# STM32U335 register map
File version: 1.0
CPU: CM33 r0p1, little endian, MPU, FPU, 4 interrupt priority bits
Registers are 32-bit, read-write, reset 0x0 unless marked. A register's access mark holds for its fields unless they carry their own. Offsets are from the block's base; [hi:lo] are bit positions; {n}, {i} and the like mark numbered series.

## RCC (part 1 of 2) — RCC register block
Base 0x40030C00
Same registers: RCC_S 0x50030C00
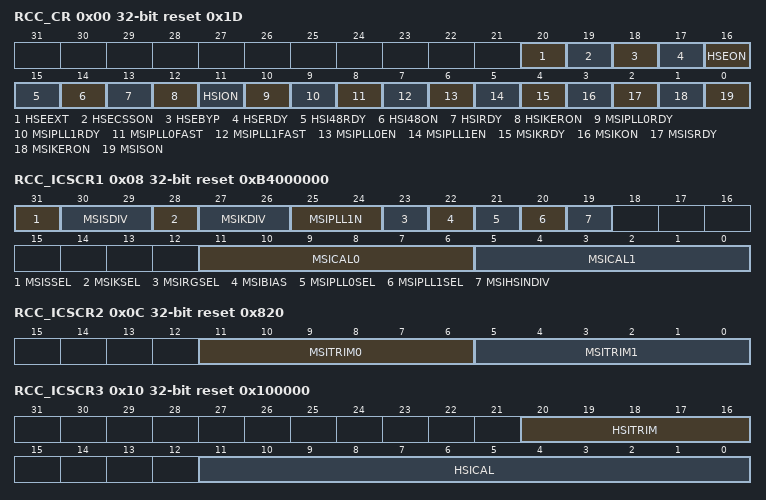
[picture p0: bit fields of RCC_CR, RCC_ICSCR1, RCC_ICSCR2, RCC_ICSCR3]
0x00 RCC_CR reset 0x1D — HSEBYP and HSEEXT are cleared upon power-on reset. They are not affected upon other types of reset.
  [20] HSEEXT — HSE external clock bypass mode Used to select the external clock mode in bypass mode. External clock mode must be configured with HSEON bit to be used by the device. This bit can be written only if the HSE oscillator is disabled. This bit is active only if the HSE bypass mode is enabled.
    0=External HSE clock analog mode; 1=External HSE clock digital mode (through I/O Schmitt trigger)
  [19] HSECSSON — Clock security system enable Used to enable the clock security system. When HSECSSON is set, the clock detector is enabled by hardware when the HSE oscillator is ready, and disabled by hardware if a HSE clock failure is detected. This bit is set only and is cleared by reset.
    0=Clock security system OFF (clock detector OFF); 1=Clock security system ON (clock detector ON if the HSE oscillator is stable, OFF if not)
  [18] HSEBYP — HSE crystal oscillator bypass Used to bypass the oscillator with an external clock. The external clock must be enabled with the HSEON bit set, to be used by the device. The HSEBYP bit can be written only if the HSE oscillator is disabled (HSEON = 0 and HSERDY = 0).
    0=HSE crystal oscillator not bypassed; 1=HSE crystal oscillator bypassed with external clock
  [17] HSERDY ro — HSE clock ready flag Set by hardware to indicate that the HSE oscillator is stable. Note: Once the HSEON bit is cleared, HSERDY goes low after six HSE clock cycles.
    0=HSE oscillator not ready; 1=HSE oscillator ready
  [16] HSEON — HSE clock enable Set and cleared by software. Cleared by hardware to stop the HSE oscillator when entering Stop, Standby, or Shutdown mode. This bit cannot be reset if the HSE oscillator is used directly or indirectly as system clock.
    0=HSE oscillator OFF; 1=HSE oscillator ON
  [15] HSI48RDY ro — HSI48 clock ready flag Set by hardware to indicate that the HSI48 oscillator is stable. This bit is set only when HSI48 is enabled by software by setting HSI48ON.
    0=HSI48 oscillator not ready; 1=HSI48 oscillator ready
  [14] HSI48ON — HSI48 clock enable Set and cleared by software. Cleared by hardware to stop the HSI48 when entering in Stop, Standby, or Shutdown mode.
    0=HSI48 oscillator OFF; 1=HSI48 oscillator ON
  [13] HSIRDY ro — HSI16 clock ready flag Set by hardware to indicate that HSI16 oscillator is stable after HSION is set. Note: When the HSI is enabled due to HSIKERON or to peripheral clock request, the HSIRDY remains cleared. Once the HSION bit is cleared, HSIRDY goes low after six HSI16 clock cycles.
    0=HSI16 oscillator not ready; 1=HSI16 oscillator ready
  [12] HSIKERON — HSI16 enable for some peripheral kernels Used to force HSI16 ON even in Stop modes. Keeping the HSI16 ON in Stop mode allows the communication speed not to be reduced by the HSI16 startup time. This bit has no effect on HSION value (refer to Peripherals clock gating and autonomous mode for more details). The HSIKERON must be configured at 0 before entering Stop 3 mode.
    0=No effect on HSI16 oscillator; 1=HSI16 oscillator forced ON even in Stop mode
  [11] HSION — HSI16 clock enable Set and cleared by software. Cleared by hardware to stop the HSI16 oscillator when entering Stop, Standby, or Shutdown mode. Set by hardware to force the HSI16 oscillator ON when STOPWUCK = 1 when leaving Stop modes, or in case of failure of the HSE crystal oscillator. This bit is set by hardware if the HSI16 is used directly or indirectly as system clock.
    0=HSI16 oscillator OFF; 1=HSI16 oscillator ON
  [10] MSIPLL0RDY ro — MSIRC0 PLL mode ready flag Set by hardware to indicate that the MSIRC0 PLL mode is locked, when the PLL mode is enabled (MSIPLL0EN = 1). This bit is cleared when the PLL mode is disabled (MSIPLL0EN = 0) or when the MSI is disabled (MSISON = MSIKON = 0).
    0=MSIRC0 PLL mode is not ready; 1=MSIRC0 PLL mode is ready
  [9] MSIPLL1RDY ro — MSIRC1 PLL mode ready flag Set by hardware to indicate that the MSIRC1 PLL mode is locked, when the PLL mode is enabled (MSIPLL1EN = 1). This bit is cleared when the PLL mode is disabled (MSIPLL1EN = 0) or when the MSI is disabled (MSISON = MSIKON = 0).
    0=MSIRC1 PLL mode is not ready; 1=MSIRC1 PLL mode is ready
  [8] MSIPLL0FAST — MSIRC0 PLL mode fast startup This bit is used only if PLL mode is selected (MSIPLL0EN = 1). The fast startup feature is not active the first time the PLL mode is selected. The fast startup is active when the MSIRC0 in PLL mode returns from switch off.
    0=MSIRC0 PLL normal startup; 1=MSIRC0 PLL fast startup
  [7] MSIPLL1FAST — MSIRC1 PLL mode fast startup This bit is used only if PLL mode is selected (MSIPLL1EN = 1). The fast startup feature is not active the first time the PLL mode is selected. The fast startup is active when the MSIRC1 in PLL mode returns from switch off.
    0=MSIRC1 PLL normal startup; 1=MSIRC1 PLL fast startup
  [6] MSIPLL0EN — MSIRC0 PLL mode enable Either MSIS or MSIK, with MSIRC0 selected, must be enabled and ready before enabling MSIRC0 PLL mode. When MSIPLL0SEL = 0, MSIPLL0EN must be enabled after LSE is enabled (LSEON enabled) and ready (LSERDY set by hardware). A hardware protection prevents from enabling MSIPLL0EN if LSE is not ready. This bit is cleared by hardware when LSE is disabled (LSEON = 0), or when the CSS on LSE detects a LSE failure (see RCC_CR). When MSIPLL0SEL = 1, MSIPLL0EN must be enabled after HSE is enabled (HSEON enabled) and ready (HSERDY set by hardware). A hardware protection prevents from enabling MSIPLL0EN if HSE is not ready, and MSIPLL0SEL is ignored. This bit is cleared by hardware when HSE is disabled (HSEON = 0) or when the CSS on HSE detects a HSE failure.
    0=MSIRC0 PLL mode disabled; 1=MSIRC0 PLL mode enabled
  [5] MSIPLL1EN — MSIRC1 PLL mode enable Either MSIS or MSIK, with MSIRC1 selected, must be enabled and ready before enabling MSIRC1 PLL mode. When MSIPLL1SEL = 0, MSIPLL1EN must be enabled after LSE is enabled (LSEON enabled) and ready (LSERDY set by hardware). A hardware protection prevents from enabling MSIPLL1EN if LSE is not ready. This bit is cleared by hardware when LSE is disabled (LSEON = 0) or when the CSS on LSE detects a LSE failure (see RCC_CSR). When MSIPLL1SEL = 1, MSIPLL1EN must be enabled after HSE is enabled (HSEON enabled) and ready (HSERDY set by hardware). A hardware protection prevents from enabling MSIPLL1EN if HSE is not ready, and MSIPLL1SEL is ignored. This bit is cleared by hardware when HSE is disabled (HSEON = 0) or when the CSS on HSE detects a HSE failure.
    0=MSIRC1 PLL mode disabled; 1=MSIRC1 PLL mode enabled
  [4] MSIKRDY ro — MSIK clock ready flag Set by hardware to indicate that the MSIK is stable. Note: Once the MSIKON bit is cleared, MSIKRDY goes low after six MSIK oscillator clock cycles.
    0=MSIK (MSI kernel) oscillator not ready; 1=MSIK (MSI kernel) oscillator ready
  [3] MSIKON — MSIK clock enable Set and cleared by software. Cleared by hardware to stop the MSIK when entering Stop, Standby, or Shutdown mode. Set by hardware to force the MSIK oscillator ON when exiting Standby or Shutdown mode. Set by hardware to force the MSIK oscillator ON when STOPWUCK = 0 or STOPKERWUCK = 0 when exiting Stop modes, or in case of a failure of the HSE oscillator.
    0=MSIK (MSI kernel) oscillator disabled; 1=MSIK (MSI kernel) oscillator enabled
  [2] MSISRDY ro — MSIS clock ready flag Set by hardware to indicate that the MSIS oscillator is stable after MSISON is set. Note: Once the MSISON bit is cleared, MSISRDY goes low after six MSIS clock cycles.
    0=MSIS (MSI system) oscillator not ready; 1=MSIS (MSI system) oscillator ready
  [1] MSIKERON — MSI enable for some peripheral kernels This bit is used to force MSI ON even in Stop mode. Keeping the MSI ON in Stop mode allows the communication speed not to be reduced by the MSI startup time. This bit has no effect on MSISON and MSIKON values (see Peripherals clock gating and autonomous mode for more details). MSIKERON must be configured at 0 before entering Stop 3 mode.
    0=No effect on MSI oscillator; 1=MSI oscillator forced ON even in Stop mode
  [0] MSISON — MSIS clock enable Set and cleared by software. Cleared by hardware to stop the MSIS oscillator when entering Stop, Standby, or Shutdown mode. Set by hardware to force the MSIS oscillator ON when exiting Standby or Shutdown mode. Set by hardware to force the MSIS oscillator ON when STOPWUCK = 0 when exiting Stop modes, or in case of a failure of the HSE oscillator. Set by hardware when used directly or indirectly as system clock.
    0=MSIS (MSI system) oscillator OFF; 1=MSIS (MSI system) oscillator ON
0x08 RCC_ICSCR1 reset 0xB4000000 (reset mask 0xFFFFF000) — X is factory-programmed.
  [31] MSISSEL — MSIS clock source selection These bits are configured by software to select the RC oscillator used to generate MSIS clock when MSIRGSEL is set. Note: MSISSEL can be modified when MSIS is OFF (MSISON = 0) or when MSIS is ready (MSISRDY = 1). MSISSEL must not be modified when MSIS is ON and NOT ready (MSISON = 1 and MSISRDY = 0). MSISSEL is kept when the device wakes up from Stop mode.
    0=MSIRC0 (96 MHz) is selected as source to generate MSIS; 1=MSIRC1 (24 MHz) is selected as source to generate MSIS
  [30:29] MSISDIV — MSIS oscillator division These bits are configured by software to choose the frequency of MSIS oscillator when MSIRGSEL is set. Note: MSISDIV can be modified when MSIS is OFF (MSISON = 0) or when MSIS is ready (MSISRDY = 1). MSISDIV must NOT be modified when MSIS is ON and NOT ready (MSISON = 1 and MSISRDY = 0). MSISDIV is kept when the device wakes up from Stop mode, except when the MSIS range is above 48 MHz. In this case, MSISDIV is changed by hardware into range 1 (48 MHz).The frequencies slightly differ in PLL mode (refer to datasheet for more information).
    0=B_0x0_MSISSEL_BIT_IN_RCC_ICSCR1__EQUAL_0 (MSIRC0/1 is selected for MSIS (range 0 around 96 MHz).); 1=B_0x1_MSISSEL_BIT_IN_RCC_ICSCR1__EQUAL_0 (MSIRC0/2 is selected for MSIS (range 1 around 48 MHz).); 2=B_0x2_MSISSEL_BIT_IN_RCC_ICSCR1__EQUAL_0 (MSIRC0/4 is selected for MSIS (range 2 around 24 MHz).); 3=B_0x3_MSISSEL_BIT_IN_RCC_ICSCR1__EQUAL_0 (MSIRC0/8 is selected for MSIS (range 3 around 12 MHz).)
  [28] MSIKSEL — MSIK clock source selection These bits are configured by software to select the RC oscillator used to generate MSIK clock when MSIRGSEL is set. Note: MSIKSEL can be modified when MSIK is OFF (MSIKON = 0) or when MSIK is ready (MSIKRDY = 1). MSIKSEL must not be modified when MSIK is ON and NOT ready (MSIKON = 1 and MSIKRDY = 0). MSIKSEL is kept when the device wakes up from Stop mode.
    0=MSIRC0 (96 MHz) is selected as source to generate MSIK; 1=MSIRC1 (24 MHz) is selected as source to generate MSIK
  [27:26] MSIKDIV — MSIK oscillator division These bits are configured by software to choose the frequency of MSIK oscillator when MSIRGSEL is set. Note: MSIKDIV can be modified when MSIK is OFF (MSIKON = 0) or when MSIK is ready (MSIKRDY = 1). MSIKDIV must NOT be modified when MSIK is ON and NOT ready (MSIKON = 1 and MSIKRDY = 0). MSIKDIV is kept when the device wakes up from Stop mode, except when the MSIK range is above 48 MHz. In this case MSIKDIV is changed by hardware into range 1 (48 MHz). The frequencies slightly differ in PLL mode (refer to datasheet for more information).
    0=B_0x0_MSIKSEL_BIT_IN_RCC_ICSCR1__EQUAL_0 (MSIRC0/1 is selected for MSIK (range 0 around 96 MHz).); 1=B_0x1_MSIKSEL_BIT_IN_RCC_ICSCR1__EQUAL_0 (MSIRC0/2 is selected for MSIK (range 1 around 48 MHz).); 2=B_0x2_MSIKSEL_BIT_IN_RCC_ICSCR1__EQUAL_0 (MSIRC0/4 is selected for MSIK (range 2 around 24 MHz).); 3=B_0x3_MSIKSEL_BIT_IN_RCC_ICSCR1__EQUAL_0 (MSIRC0/8 is selected for MSIK (range 3 around 12 MHz).)
  [25:24] MSIPLL1N — MSIRC1 PLL mode with LSE multiplication factor These bits select the frequency of MSIRC1 in PLL mode, impacting range 4, 5, 6 and 7 frequencies. These bits have no effect when the PLL mode is disabled. Note: Refer to Table 97: MSIS and MSIK ranges per internal MSIRCs (PLL mode disabled) for MSIS/MSIK clock output depends on input and configuration.
  [23] MSIRGSEL — MSI clock range selection Set by software to select the MSIS/MSIK frequency range, using MSISSEL/MSIKSEL and MSISDIV[1:0]/MSIKDIV[1:0] bit fields. Writing 0 has no effect. After exiting Standby or Shutdown mode, or after a reset, this bit is at 0, and the MSIS and MSIK ranges are provided by MSISDIVS[1:0] and MSIKDIVS[1:0] in RCC_CSR.
    0=MSIS/MSIK ranges provided by MSISDIVS[1:0] and MSIKDIVS[1:0] in RCC_CSR; 1=MSIS/MSIK ranges provided by MSISDIV[1:0] and MSIKDIV[1:0] in RCC_ICSCR1
  [22] MSIBIAS — MSI bias mode selection By default, the MSI bias (for both MSIS and MSIK) is in continuous mode in order to maintain the output clocks accuracy. Setting this bit reduces the MSI consumption when the device is in Stop 1 or Stop 2 mode, or when the regulator is in range 2, but it decreases the MSI accuracy
    0=MSI bias continuous mode (clock accuracy fast settling time); 1=MSI bias sampling mode when the device is in Stop 1 or Stop 2 mode, or when the regulator is in range 2
  [21] MSIPLL0SEL — MSIRC0 PLL mode input clock selection LSE or HSE must be enabled and ready before selecting this oscillator as MSIRC0 input clock.
    0=LSE is used as MSIRC0 input clock when PLL mode is selected; 1=HSE or HSE/2 is used as MSIRC0 input clock when PLL mode is selected
  [20] MSIPLL1SEL — MSIRC1 PLL mode input clock selection LSE or HSE must be enabled and ready before selecting this oscillator as MSIRC1 input clock.
    0=LSE is used as MSIRC1 input clock when PLL mode is selected; 1=HSE or HSE/2 is used as MSIRC1 input clock when PLL mode is selected
  [19] MSIHSINDIV — MSIRCx (x = 0, 1) PLL mode HSE input division This bit is used to divide the HSE input clock when used by MSIRCx (x = 0, 1) in PLL mode. MSIRCx high-speed input clock must be 16 MHz.
    0=HSE (16 MHz) is used as MSI input clock when PLL mode with high-speed clock is selected; 1=HSE (32 MHz)/2 is used as MSI input clock when PLL mode with high-speed clock is selected
  [11:6] MSICAL0 ro — MSIRC0 clock calibration for MSI ranges 0 to 3 These bits are initialized at startup with the factory-programmed MSIRC0 calibration trim value for ranges 0 to 3. When MSITRIM0 is written, MSICAL0 is updated with the sum of MSITRIM0[5:0] and the factory-programmed calibration trim value MSIRC0[5:0]. There is no hardware protection to limit a potential overflow due to the addition of MSITRIM bit field and factory program bit field for this calibration value. Control must be managed by software at user level.
  [5:0] MSICAL1 ro — MSIRC1 clock calibration for MSI ranges 4 to 7 These bits are initialized at startup with the factory-programmed MSIRC1 calibration trim value for ranges 4 to 7. When MSITRIM1 is written, MSICAL1 is updated with the sum of MSITRIM1[5:0] and the factory-programmed calibration trim value MSIRC1[5:0]. There is no hardware protection to limit a potential overflow due to the addition of MSITRIM bit field and factory program bit field for this calibration value. Control must be managed by software at user level.
0x0C RCC_ICSCR2 reset 0x820
  [11:6] MSITRIM0 — MSIRC0 clock trimming for ranges 0 to 3 These bits provide an additional user-programmable trimming value that is added to the factory-programmed calibration trim value MSIRC0[5:0] bits. It can be programmed to adjust to voltage and temperature variations that influence the frequency of the MSI.
  [5:0] MSITRIM1 — MSIRC1 clock trimming for ranges 4 to 7 These bits provide an additional user-programmable trimming value that is added to the factory-programmed calibration trim value MSIRC1[5:0] bits. It can be programmed to adjust to voltage and temperature variations that influence the frequency of the MSI.
0x10 RCC_ICSCR3 reset 0x100000 (reset mask 0xFFFFF000) — X is factory-programmed.
  [20:16] HSITRIM — HSI clock trimming These bits provide an additional user-programmable trimming value. It can be programmed to adjust to voltage and temperature variations that influence the frequency of the HSI.
  [11:0] HSICAL ro — HSI clock calibration These bits are initialized at startup with the factory-programmed HSI calibration trim value.
0x14 RCC_CRRCR ro (reset mask 0xFFFFF000) — X is factory-programmed.
  [8:0] HSI48CAL — HSI48 clock calibration These bits are initialized at startup with the factory-programmed HSI48 calibration trim value.
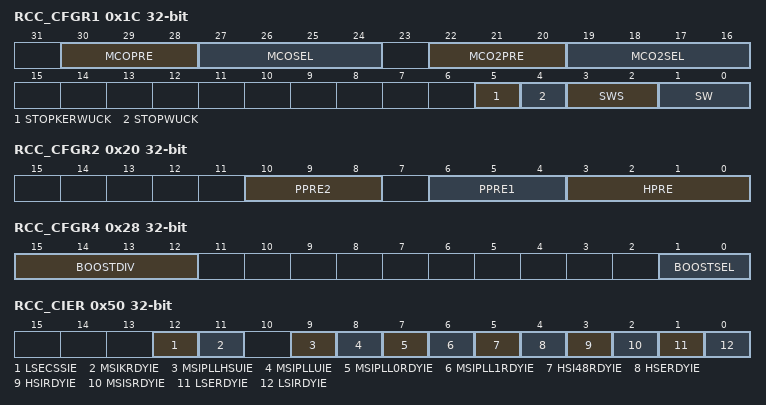
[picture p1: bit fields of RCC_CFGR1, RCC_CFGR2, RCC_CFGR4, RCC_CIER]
0x1C RCC_CFGR1 — 1 or 2 wait states are inserted only if the access occurs during clock source switch.
  [30:28] MCOPRE — Microcontroller clock output prescaler This prescaler must be configured before MCO output is enabled.
    0=MCO divided by 1; 1=MCO divided by 2; 2=MCO divided by 4; 3=MCO divided by 8; 4=MCO divided by 16; 5=MCO divided by 32; 6=MCO divided by 64; 7=MCO divided by 128
  [27:24] MCOSEL — Microcontroller clock output Set and cleared by software. Others: Reserved Note: This clock output may have some truncated cycles at startup or during MCO clock source switching.
    0=MCO output disabled, no clock on MCO; 1=SYSCLK system clock selected; 2=MSIS clock selected; 3=HSI16 clock selected; 4=HSE clock selected; 5=LSI clock selected; 6=LSE clock selected; 7=HSI48 clock selected; 8=MSIK clock selected
  [22:20] MCO2PRE — Microcontroller clock output 2 prescaler This prescaler must be configured before MCO2 output is enabled.
    0=MCO2 divided by 1; 1=MCO2 divided by 2; 2=MCO2 divided by 4; 3=MCO2 divided by 8; 4=MCO2 divided by 16; 5=MCO2 divided by 32; 6=MCO2 divided by 64; 7=MCO2 divided by 128
  [19:16] MCO2SEL — Microcontroller clock output 2 Others: Reserved Note: This clock output may have some truncated cycles at startup or during MCO clock source switching.
    0=MCO2 output disabled, no clock on MCO2; 1=SYSCLK system clock selected; 2=MSIS clock selected; 3=HSI16 clock selected; 4=HSE clock selected; 5=LSI clock selected; 6=LSE clock selected; 7=HSI48 clock selected; 8=MSIK clock selected
  [5] STOPKERWUCK — Wake-up from Stop kernel clock automatic enable selection This bit is used to enable automatically another oscillator than the one used as wake-up from Stop system clock. This helps to save its wake-up time when this oscillator is needed as peripheral independent kernel clock. Note: STOPKERWUCK must be programmed with the same value than STOPWUCK to avoid the other oscillator power-on after CSS event or Stop mode exit.
    0=MSIK oscillator automatically enabled when exiting Stop mode or when a CSS on HSE event occurs; 1=HSI16 oscillator automatically enabled when exiting Stop mode or when a CSS on HSE event occurs
  [4] STOPWUCK — Wake-up from Stop and CSS backup clock selection This bit is used to select the system clock used when exiting Stop mode. The selected clock is also used as emergency clock for the clock security system on HSE. Note: STOPWUCK must not be modified when the CSS is enabled by HSECSSON bit in RCC_CR and the system clock is HSE (SWS = 10) or a switch on HSE is requested (SW = 10). STOPKERWUCK must be programmed with the same value than STOPWUCK to avoid the other oscillator power-on after CSS event or Stop mode exit.
    0=MSIS oscillator selected as wake-up from stop clock and CSS backup clock; 1=HSI16 oscillator selected as wake-up from stop clock and CSS backup clock
  [3:2] SWS ro — System clock switch status Set and cleared by hardware to indicate which clock source is used as system clock.
    0=MSIS oscillator used as system clock; 1=HSI16 oscillator used as system clock; 2=HSE used as system clock
  [1:0] SW — System clock switch These bits are used to select system clock source (SYSCLK). Configured by hardware to force MSIS oscillator selection when exiting Standby or Shutdown mode. Configured by hardware to force MSIS or HSI16 oscillator selection when exiting Stop mode, or in case of HSE oscillator failure, depending on STOPWUCK value.
    0=MSIS selected as system clock; 1=HSI16 selected as system clock; 2=HSE selected as system clock
0x20 RCC_CFGR2 — From 0 to 15 wait states are inserted if the access occurs when the APB or AHB prescalers values update is ongoing.
  [10:8] PPRE2 — APB2 prescaler These bits are used to configure the division factor of the APB2 clock (PCLK2).
    {v}=PCLK2 = HCLK not divided (v=0..3); 4=PCLK2 = HCLK divided by 2; 5=PCLK2 = HCLK divided by 4; 6=PCLK2 = HCLK divided by 8; 7=PCLK2 = HCLK divided by 16
  [6:4] PPRE1 — APB1 prescaler These bits are used to configure the division factor of the APB1 clock (PCLK1).
    {v}=PCLK1 = HCLK not divided (v=0..3); 4=PCLK1 = HCLK divided by 2; 5=PCLK1 = HCLK divided by 4; 6=PCLK1 = HCLK divided by 8; 7=PCLK1 = HCLK divided by 16
  [3:0] HPRE — AHB prescaler These bits are used to configure the division factor of the AHB clock (HCLK). Depending on the device voltage range, the software must set these bits correctly to ensure that the system frequency does not exceed the maximum allowed frequency (for more details, refer to Table 99: Bus maximum frequency). After a write operation to these bits and before decreasing the voltage range, this register must be read to be sure that the new value is taken into account.
    {v}=HCLK = SYSCLK not divided (v=0..7); 8=HCLK = SYSCLK divided by 2; 9=HCLK = SYSCLK divided by 4; 10=HCLK = SYSCLK divided by 8; 11=HCLK = SYSCLK divided by 16; 12=HCLK = SYSCLK divided by 64; 13=HCLK = SYSCLK divided by 128; 14=HCLK = SYSCLK divided by 256; 15=HCLK = SYSCLK divided by 512
0x24 RCC_CFGR3 — From 0 to 15 wait states are inserted if the access occurs when the APB or AHB prescalers values update is ongoing.
  [6:4] PPRE3 — APB3 prescaler These bits are used to configure the division factor of the APB3 clock (PCLK3).
    {v}=PCLK3 = HCLK not divided (v=0..3); 4=PCLK3 = HCLK divided by 2; 5=PCLK3 = HCLK divided by 4; 6=PCLK3 = HCLK divided by 8; 7=PCLK3 = HCLK divided by 16
0x28 RCC_CFGR4
  [15:12] BOOSTDIV — EPOD booster input clock prescaler These bits are used to configure the division factor for the EPOD booster input clock, when it is HSI16 or HSE. The division factor is forced by hardware when the EPOD booster input clock is MSIS. In this case, these bits are read only. The EPOD booster input frequency is BOOSTSEL oscillator/BOOSTDIV, and must be between 3 and 16 MHz (see Section 10.1: RCC introduction). Others: Reserved
    0=Divided by 1 (bypass); 1=Divided by 2; 2=Divided by 4; 3=Divided by 6; 4=Divided by 8; 5=Divided by 10; 6=Divided by 12; 7=Divided by 14; 8=Divided by 16
  [1:0] BOOSTSEL — EPOD booster input clock source selection These bits are used to selected to EPOD booster input clock source oscillator. The booster clock source must be enabled and configured before enabling the booster. BOOSTSEL must be kept at 00 to save power when the booster is disabled.
    0=No clock; 1=MSIS selected as EPOD booster clock source; 2=HSI16 selected as EPOD booster clock source; 3=HSE selected as EPOD booster clock source
0x50 RCC_CIER
  [12] LSECSSIE — LSE clock security system interrupt enable
    0=LSE CSS interrupt disabled; 1=LSE CSS interrupt enabled
  [11] MSIKRDYIE — MSIK ready interrupt enable
    0=MSIK ready interrupt disabled; 1=MSIK ready interrupt enabled
  [9] MSIPLLHSUIE — MSI PLL mode with HSE unlock interrupt enable
    0=MSI PLL mode with HSE unlock interrupt disabled; 1=MSI PLL mode with HSE unlock interrupt enabled
  [8] MSIPLLUIE — MSI PLL mode with LSE unlock interrupt enable
    0=MSI PLL mode with LSE unlock interrupt disabled; 1=MSI PLL mode with LSE unlock interrupt enabled
  [7] MSIPLL0RDYIE — MSIRC0 PLL mode ready interrupt enable
    0=MSIRC0 PLL mode lock interrupt disabled; 1=MSIRC0 PLL mode lock interrupt enabled
  [6] MSIPLL1RDYIE — MSIRC1 PLL mode ready interrupt enable
    0=MSIRC1 PLL mode lock interrupt disabled; 1=MSIRC1 PLL mode lock interrupt enabled
  [5] HSI48RDYIE — HSI48 ready interrupt enable
    0=HSI48 ready interrupt disabled; 1=HSI48 ready interrupt enabled
  [4] HSERDYIE — HSE ready interrupt enable
    0=HSE ready interrupt disabled; 1=HSE ready interrupt enabled
  [3] HSIRDYIE — HSI16 ready interrupt enable
    0=HSI16 ready interrupt disabled; 1=HSI16 ready interrupt enabled
  [2] MSISRDYIE — MSIS ready interrupt enable
    0=MSIS ready interrupt disabled; 1=MSIS ready interrupt enabled
  [1] LSERDYIE — LSE ready interrupt enable
    0=LSE ready interrupt disabled; 1=LSE ready interrupt enabled
  [0] LSIRDYIE — LSI ready interrupt enable
    0=LSI ready interrupt disabled; 1=LSI ready interrupt enabled
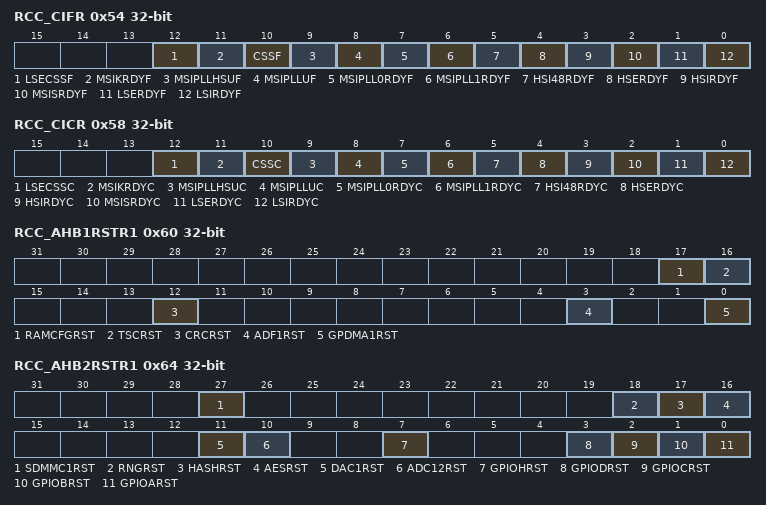
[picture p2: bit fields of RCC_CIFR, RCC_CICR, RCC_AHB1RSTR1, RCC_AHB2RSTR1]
0x54 RCC_CIFR ro
  [12] LSECSSF — LSE clock security system interrupt flag Set by hardware when a failure is detected on LSE and LSECSSIE is set. Cleared by software setting the LSECSSC bit.
    0=No LSE clock security interrupt; 1=LSE clock security interrupt
  [11] MSIKRDYF — MSIK ready interrupt flag Set by hardware when the MSIK clock becomes stable and MSIKRDYIE is set. Cleared by software setting the MSIKRDYC bit.
    0=No MSIK oscillator clock ready interrupt; 1=MSIK oscillator clock ready interrupt
  [10] CSSF — Clock security system interrupt flag Set by hardware when a failure is detected in the HSE oscillator. Cleared by software setting the CSSC bit.
    0=No HSE clock security interrupt; 1=HSE clock security interrupt
  [9] MSIPLLHSUF — MSI PLL mode with HSE unlock interrupt flag Set by hardware when the PLL mode of MSI using HSE input is unlocked due to HSE failure and MSIPLLHSUIE is set. This occurs when MSI PLL mode using HSE is ready and HSE clock is stopped. In this case, the MSI automatically exits the PLL mode, and MSIPLL0EN/MSIPLL1EN must be cleared by software. Cleared by software setting the MSIPLLHSUC bit.
    0=No MSI PLL mode with HSE unlock interrupt; 1=MSI PLL mode with HSE unlock interrupt
  [8] MSIPLLUF — MSI PLL mode with LSE unlock interrupt flag Set by hardware when the PLL mode of MSI using LSE input is unlocked due to LSE failure and MSIPLLUIE is set. This occurs when MSI PLL mode using LSE is ready and LSE clock is stopped. In this case, the MSI automatically exits the PLL mode and MSIPLL0EN/MSIPLL1EN must be cleared by software. Cleared by software setting the MSIPLLUC bit.
    0=No MSI PLL mode with LSE unlock interrupt; 1=MSI PLL mode with LSE unlock interrupt
  [7] MSIPLL0RDYF — MSIRC0 PLL mode ready interrupt flag Set by hardware when the MSIRC0 clock in PLL mode becomes stable and MSIPLL0RDYIE is set. Cleared by software setting the MSIPLL0RDYC bit.
    0=No MSIRC0 PLL mode ready interrupt; 1=MSIRC0 PLL mode ready interrupt
  [6] MSIPLL1RDYF — MSIRC1 PLL mode ready interrupt enable Set by hardware when the MSIRC1 clock in PLL mode becomes stable and MSIPLL1RDYIE is set. Cleared by software setting the MSIPLL1RDYC bit.
    0=No MSIRC1 PLL mode ready interrupt; 1=MSIRC1 PLL mode ready interrupt
  [5] HSI48RDYF — HSI48 ready interrupt flag Set by hardware when the HSI48 clock becomes stable and HSI48RDYIE is set. Cleared by software setting the HSI48RDYC bit.
    0=No HSI48 ready interrupt; 1=HSI48 ready interrupt
  [4] HSERDYF — HSE ready interrupt flag Set by hardware when the HSE clock becomes stable and HSERDYIE is set. Cleared by software setting the HSERDYC bit.
    0=No HSE ready interrupt; 1=HSE ready interrupt
  [3] HSIRDYF — HSI16 ready interrupt flag Set by hardware when the HSI16 clock becomes stable and HSIRDYIE is set in a response to setting the HSION (see RCC_CR). When HSION is not set but the HSI16 oscillator is enabled by the peripheral through a clock request, this bit is not set and no interrupt is generated. Cleared by software setting the HSIRDYC bit.
    0=No HSI16 ready interrupt; 1=HSI16 ready interrupt
  [2] MSISRDYF — MSIS ready interrupt flag Set by hardware when the MSIS clock becomes stable and MSISRDYIE is set. Cleared by software setting the MSISRDYC bit.
    0=No MSIS ready interrupt; 1=MSIS ready interrupt
  [1] LSERDYF — LSE ready interrupt flag Set by hardware when the LSE clock becomes stable and LSERDYIE is set. Cleared by software setting the LSERDYC bit.
    0=No LSE ready interrupt; 1=LSE ready interrupt
  [0] LSIRDYF — LSI ready interrupt flag Set by hardware when the LSI clock becomes stable and LSIRDYIE is set. Cleared by software setting the LSIRDYC bit.
    0=No LSI ready interrupt; 1=LSI ready interrupt
0x58 RCC_CICR wo
  [12] LSECSSC — LSE CSS interrupt clear Writing this bit to 1 clears the LSECSSF flag. Writing 0 has no effect.
  [11] MSIKRDYC — MSIK oscillator ready interrupt clear Writing this bit to 1 clears the MSIKRDYF flag. Writing 0 has no effect.
  [10] CSSC — Clock security system interrupt clear Writing this bit to 1 clears the CSSF flag. Writing 0 has no effect.
  [9] MSIPLLHSUC — MSI PLL mode with HSE unlock interrupt clear Writing this bit to 1 clears the MSIPLLHSUF flag. Writing 0 has no effect.
  [8] MSIPLLUC — MSI PLL mode with LSE unlock interrupt clear Writing this bit to 1 clears the MSIPLLLSUF flag. Writing 0 has no effect.
  [7] MSIPLL0RDYC — MSIRC0 PLL mode ready interrupt clear Writing this bit to 1 clears the MSIPLLHSUF flag. Writing 0 has no effect.
  [6] MSIPLL1RDYC — MSIRC1 PLL mode ready interrupt clear Writing this bit to 1 clears the MSIPLLLSUF flag. Writing 0 has no effect.
  [5] HSI48RDYC — HSI48 ready interrupt clear Writing this bit to 1 clears the HSI48RDYF flag. Writing 0 has no effect.
  [4] HSERDYC — HSE ready interrupt clear Writing this bit to 1 clears the HSERDYF flag. Writing 0 has no effect.
  [3] HSIRDYC — HSI16 ready interrupt clear Writing this bit to 1 clears the HSIRDYF flag. Writing 0 has no effect.
  [2] MSISRDYC — MSIS ready interrupt clear Writing this bit to 1 clears the MSISRDYF flag. Writing 0 has no effect.
  [1] LSERDYC — LSE ready interrupt clear Writing this bit to 1 clears the LSERDYF flag. Writing 0 has no effect.
  [0] LSIRDYC — LSI ready interrupt clear Writing this bit to 1 clears the LSIRDYF flag. Writing 0 has no effect.
0x60 RCC_AHB1RSTR1
  [17] RAMCFGRST — RAMCFG reset
    0=No effect; 1=Reset RAMCFG
  [16] TSCRST — TSC reset
    0=No effect; 1=Reset TSC
  [12] CRCRST — CRC reset
    0=No effect; 1=Reset CRC
  [3] ADF1RST — ADF1 reset
    0=No effect; 1=Reset ADF1
  [0] GPDMA1RST — GPDMA1 reset
    0=No effect; 1=Reset GPDMA1
0x64 RCC_AHB2RSTR1
  [27] SDMMC1RST — SDMMC1 reset
    0=No effect; 1=Reset SDMMC1
  [18] RNGRST — Random number generator reset
    0=No effect; 1=Reset RNG
  [17] HASHRST — HASH reset
    0=No effect; 1=Reset HASH
  [16] AESRST — AES hardware accelerator reset
    0=No effect; 1=Reset AES
  [11] DAC1RST — DAC1 reset
    0=No effect; 1=Reset DAC1
  [10] ADC12RST — ADC12 reset
    0=No effect; 1=Reset ADC12
  [7] GPIOHRST — I/O port i reset (i = H to A) Note: Port F is only available on STM32U3B5/3C5.
    0=No effect; 1=Reset I/O port i
  [3] GPIODRST — I/O port i reset (i = H to A) Note: Port F is only available on STM32U3B5/3C5.
    0=No effect; 1=Reset I/O port i
  [2] GPIOCRST — I/O port i reset (i = H to A) Note: Port F is only available on STM32U3B5/3C5.
    0=No effect; 1=Reset I/O port i
  [1] GPIOBRST — I/O port i reset (i = H to A) Note: Port F is only available on STM32U3B5/3C5.
    0=No effect; 1=Reset I/O port i
  [0] GPIOARST — I/O port i reset (i = H to A) Note: Port F is only available on STM32U3B5/3C5.
    0=No effect; 1=Reset I/O port i
0x68 RCC_AHB2RSTR2
  [4] OCTOSPI1RST — OCTOSPI1 reset
    0=No effect; 1=Reset OCTOSPI1
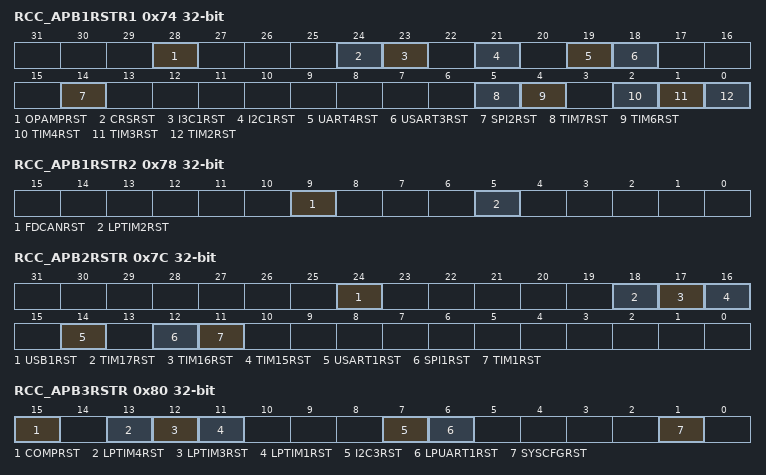
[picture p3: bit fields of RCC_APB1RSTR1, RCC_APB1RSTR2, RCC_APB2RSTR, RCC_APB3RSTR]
0x74 RCC_APB1RSTR1
  [28] OPAMPRST — OPAMP reset
    0=No effect; 1=Reset OPAMP
  [24] CRSRST — CRS reset
    0=No effect; 1=Reset the CRS
  [23] I3C1RST — I3C1 reset
    0=No effect; 1=Reset the I3C1
  [21] I2C1RST — I2C1 reset
    0=No effect; 1=Reset the I2C1
  [19] UART4RST — UART4 reset
    0=No effect; 1=Reset UART4
  [18] USART3RST — USART3 reset
    0=No effect; 1=Reset USART3
  [14] SPI2RST — SPI2 reset
    0=No effect; 1=Reset SPI2
  [5] TIM7RST — TIMj reset
    0=No effect; 1=Reset TIMj
  [4] TIM6RST — TIMj reset
    0=No effect; 1=Reset TIMj
  [2] TIM4RST — TIMj reset
    0=No effect; 1=Reset TIMj
  [1] TIM3RST — TIMj reset
    0=No effect; 1=Reset TIMj
  [0] TIM2RST — TIMj reset
    0=No effect; 1=Reset TIMj
0x78 RCC_APB1RSTR2
  [9] FDCANRST — FDCAN1 and FDCAN2 reset Note: FDCAN2 is only available on STM32U3B5/3C5.
    0=No effect; 1=Reset FDCAN1 and FDCAN2
  [5] LPTIM2RST — LPTIM2 reset
    0=No effect; 1=Reset LPTIM2
0x7C RCC_APB2RSTR
  [24] USB1RST — USB1 reset
    0=No effect; 1=Reset USB1
  [18] TIM17RST — TIMi reset
    0=No effect; 1=Reset TIMi
  [17] TIM16RST — TIMi reset
    0=No effect; 1=Reset TIMi
  [16] TIM15RST — TIMi reset
    0=No effect; 1=Reset TIMi
  [14] USART1RST — USART1 reset
    0=No effect; 1=Reset USART1
  [12] SPI1RST — SPI1 reset
    0=No effect; 1=Reset SPI1
  [11] TIM1RST — TIM1 reset
    0=No effect; 1=Reset TIM1
0x80 RCC_APB3RSTR
  [15] COMPRST — COMP reset
    0=No effect; 1=Reset COMP
  [13] LPTIM4RST — LPTIMi reset
    0=No effect; 1=Reset LPTIMi
  [12] LPTIM3RST — LPTIMi reset
    0=No effect; 1=Reset LPTIMi
  [11] LPTIM1RST — LPTIM1 reset
    0=No effect; 1=Reset LPTIM1
  [7] I2C3RST — I2C3 reset
    0=No effect; 1=Reset I2C3
  [6] LPUART1RST — LPUART1 reset
    0=No effect; 1=Reset LPUART1
  [1] SYSCFGRST — SYSCFG reset
    0=No effect; 1=Reset SYSCFG
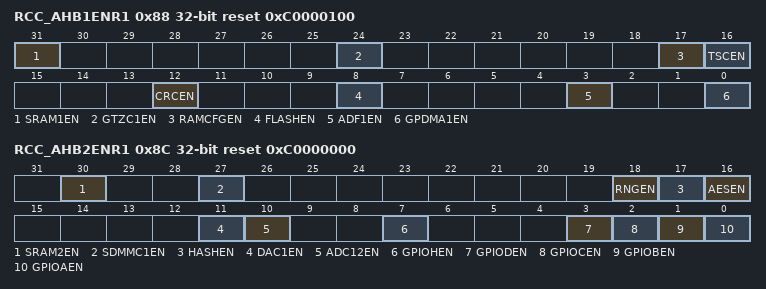
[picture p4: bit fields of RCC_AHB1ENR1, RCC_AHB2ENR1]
0x88 RCC_AHB1ENR1 reset 0xC0000100
  [31] SRAM1EN — SRAM1 clock enable
    0=SRAM1 clock disabled; 1=SRAM1 clock enabled
  [24] GTZC1EN — GTZC1 clock enable
    0=GTZC1 clock disabled; 1=GTZC1 clock enabled
  [17] RAMCFGEN — RAMCFG clock enable
    0=RAMCFG clock disabled; 1=RAMCFG clock enabled
  [16] TSCEN — Touch sensing controller clock enable
    0=TSC clock disabled; 1=TSC clock enabled
  [12] CRCEN — CRC clock enable
    0=CRC clock disabled; 1=CRC clock enabled
  [8] FLASHEN — FLASH clock enable This bit can be disabled only when the flash memory is in power-down mode.
    0=FLASH clock disabled; 1=FLASH clock enabled
  [3] ADF1EN — ADF1 clock enable
    0=ADF1 clock disabled; 1=ADF1 clock enabled
  [0] GPDMA1EN — GPDMA1 clock enable
    0=GPDMA1 clock disabled; 1=GPDMA1 clock enabled
0x8C RCC_AHB2ENR1 reset 0xC0000000
  [30] SRAM2EN — SRAM2 clock enable
    0=SRAM2 clock disabled; 1=SRAM2 clock enabled
  [27] SDMMC1EN — SDMMC1 clock enable
    0=SDMMC1 clock disabled; 1=SDMMC1 clock enabled
  [18] RNGEN — RNG clock enable
    0=RNG clock disabled; 1=RNG clock enabled
  [17] HASHEN — HASH clock enable
    0=HASH clock disabled; 1=HASH clock enabled
  [16] AESEN — AES clock enable
    0=AES clock disabled; 1=AES clock enabled
  [11] DAC1EN — DAC1 clock enable
    0=DAC1 clock disabled; 1=DAC1 clock enabled
  [10] ADC12EN — ADC12 clock enable
    0=ADC12 clock disabled; 1=ADC12 clock enabled
  [7] GPIOHEN — I/O port i clock enable (i = H to A) Note: Port F is only available on STM32U3B5/3C5.
    0=I/O port i clock disabled; 1=I/O port i clock enabled
  [3] GPIODEN — I/O port i clock enable (i = H to A) Note: Port F is only available on STM32U3B5/3C5.
    0=I/O port i clock disabled; 1=I/O port i clock enabled
  [2] GPIOCEN — I/O port i clock enable (i = H to A) Note: Port F is only available on STM32U3B5/3C5.
    0=I/O port i clock disabled; 1=I/O port i clock enabled
  [1] GPIOBEN — I/O port i clock enable (i = H to A) Note: Port F is only available on STM32U3B5/3C5.
    0=I/O port i clock disabled; 1=I/O port i clock enabled
  [0] GPIOAEN — I/O port i clock enable (i = H to A) Note: Port F is only available on STM32U3B5/3C5.
    0=I/O port i clock disabled; 1=I/O port i clock enabled
0x90 RCC_AHB2ENR2
  [4] OCTOSPI1EN — OCTOSPI1 clock enable
    0=OCTOSPI1 clock disabled; 1=OCTOSPI1 clock enabled
0x94 RCC_AHB1ENR2
  [2] PWREN — PWR clock enable
    0=PWR clock disabled; 1=PWR clock enabled
